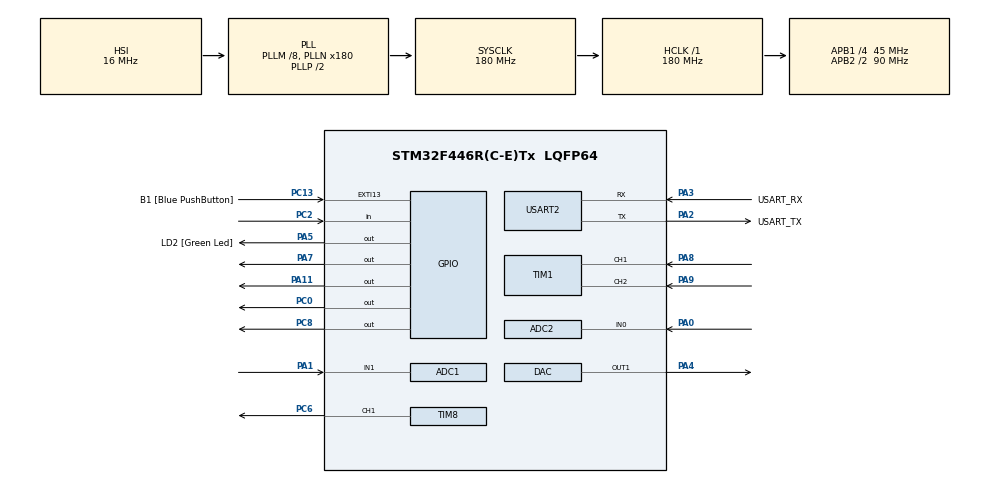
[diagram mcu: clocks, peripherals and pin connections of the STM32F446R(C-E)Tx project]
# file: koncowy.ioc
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ADC1.Channel-0\#ChannelRegularConversion=ADC_CHANNEL_1
ADC1.NbrOfConversionFlag=1
ADC1.Rank-0\#ChannelRegularConversion=1
ADC1.SamplingTime-0\#ChannelRegularConversion=ADC_SAMPLETIME_3CYCLES
ADC1.master=1
ADC2.Channel-0\#ChannelRegularConversion=ADC_CHANNEL_0
ADC2.ClockPrescaler=ADC_CLOCK_SYNC_PCLK_DIV4
ADC2.ContinuousConvMode=DISABLE
ADC2.DMAContinuousRequests=ENABLE
ADC2.ExternalTrigConv=ADC_EXTERNALTRIGCONV_T8_TRGO
ADC2.InjNumberOfConversion=0
ADC2.NbrOfConversionFlag=1
ADC2.Rank-0\#ChannelRegularConversion=1
ADC2.SamplingTime-0\#ChannelRegularConversion=ADC_SAMPLETIME_3CYCLES
Dma.ADC2.0.Direction=DMA_PERIPH_TO_MEMORY
Dma.ADC2.0.FIFOMode=DMA_FIFOMODE_DISABLE
Dma.ADC2.0.Instance=DMA2_Stream2
Dma.ADC2.0.MemDataAlignment=DMA_MDATAALIGN_HALFWORD
Dma.ADC2.0.MemInc=DMA_MINC_ENABLE
Dma.ADC2.0.Mode=DMA_CIRCULAR
Dma.ADC2.0.PeriphDataAlignment=DMA_PDATAALIGN_HALFWORD
Dma.ADC2.0.PeriphInc=DMA_PINC_DISABLE
Dma.ADC2.0.Priority=DMA_PRIORITY_LOW
Dma.Request0=ADC2
Dma.Request1=USART2_RX
Dma.USART2_RX.1.Direction=DMA_PERIPH_TO_MEMORY
Dma.USART2_RX.1.FIFOMode=DMA_FIFOMODE_DISABLE
Dma.USART2_RX.1.Instance=DMA1_Stream5
Dma.USART2_RX.1.MemDataAlignment=DMA_MDATAALIGN_BYTE
Dma.USART2_RX.1.MemInc=DMA_MINC_ENABLE
Dma.USART2_RX.1.Mode=DMA_NORMAL
Dma.USART2_RX.1.PeriphDataAlignment=DMA_PDATAALIGN_BYTE
Dma.USART2_RX.1.PeriphInc=DMA_PINC_DISABLE
Dma.USART2_RX.1.Priority=DMA_PRIORITY_LOW
Mcu.Family=STM32F4
Mcu.Name=STM32F446R(C-E)Tx
Mcu.Package=LQFP64
NVIC.ADC_IRQn=true\:0\:10\:false\:false\:true\:true\:true\:true
NVIC.DMA1_Stream5_IRQn=true\:0\:0\:false\:false\:true\:false\:true\:true
NVIC.DMA2_Stream2_IRQn=true\:0\:2\:false\:false\:true\:false\:true\:true
NVIC.PriorityGroup=NVIC_PRIORITYGROUP_0
NVIC.TIM8_CC_IRQn=true\:0\:6\:false\:false\:true\:true\:true\:true
NVIC.USART2_IRQn=true\:0\:0\:false\:false\:true\:true\:true\:true
PA0-WKUP.Signal=ADCx_IN0
PA1.Signal=ADCx_IN1
PA11.Signal=GPIO_Output
PA13.GPIO_Label=TMS
PA13.Mode=Serial_Wire
PA13.Signal=SYS_JTMS-SWDIO
PA14.GPIO_Label=TCK
PA14.Mode=Serial_Wire
PA14.Signal=SYS_JTCK-SWCLK
PA2.GPIO_Label=USART_TX
PA2.Mode=Asynchronous
PA2.Signal=USART2_TX
PA3.GPIO_Label=USART_RX
PA3.Mode=Asynchronous
PA3.Signal=USART2_RX
PA4.Signal=COMP_DAC1_group
PA5.GPIO_Label=LD2 [Green Led]
PA5.Signal=GPIO_Output
PA7.Signal=GPIO_Output
PA8.Signal=S_TIM1_CH1
PA9.Signal=S_TIM1_CH2
PB3.GPIO_Label=SWO
PB3.Signal=SYS_JTDO-SWO
PC0.Signal=GPIO_Output
PC13.GPIO_Label=B1 [Blue PushButton]
PC13.GPIO_ModeDefaultEXTI=GPIO_MODE_IT_FALLING
PC13.Signal=GPXTI13
PC14-OSC32_IN.Mode=LSE-External-Oscillator
PC14-OSC32_IN.Signal=RCC_OSC32_IN
PC15-OSC32_OUT.Mode=LSE-External-Oscillator
PC15-OSC32_OUT.Signal=RCC_OSC32_OUT
PC2.Signal=GPIO_Input
PC6.Signal=S_TIM8_CH1
PC8.Signal=GPIO_Output
PH0-OSC_IN.Mode=HSE-External-Oscillator
PH0-OSC_IN.Signal=RCC_OSC_IN
PH1-OSC_OUT.Mode=HSE-External-Oscillator
PH1-OSC_OUT.Signal=RCC_OSC_OUT
ProjectManager.HeapSize=0x200
ProjectManager.StackSize=0x400
ProjectManager.TargetToolchain=STM32CubeIDE
RCC.48MHZClocksFreq_Value=84000000
RCC.AHBFreq_Value=180000000
RCC.APB1CLKDivider=RCC_HCLK_DIV4
RCC.APB1Freq_Value=45000000
RCC.APB1TimFreq_Value=90000000
RCC.APB2CLKDivider=RCC_HCLK_DIV2
RCC.APB2Freq_Value=90000000
RCC.APB2TimFreq_Value=180000000
RCC.CortexFreq_Value=180000000
RCC.FLatency-AdvancedSettings=FLASH_LATENCY_5
RCC.HCLKFreq_Value=180000000
RCC.HSE_VALUE=8000000
RCC.HSI_VALUE=16000000
RCC.PLLM=8
RCC.PLLN=180
RCC.SYSCLKFreq_VALUE=180000000
RCC.SYSCLKSource=RCC_SYSCLKSOURCE_PLLCLK
RCC.USBFreq_Value=180000000
RCC.VCOOutputFreq_Value=360000000
SH.ADCx_IN0.0=ADC2_IN0,IN0
SH.ADCx_IN1.0=ADC1_IN1,IN1
SH.COMP_DAC1_group.0=DAC_OUT1,DAC_OUT1
SH.S_TIM1_CH1.0=TIM1_CH1,Encoder_Interface
SH.S_TIM1_CH2.0=TIM1_CH2,Encoder_Interface
SH.S_TIM8_CH1.0=TIM8_CH1,PWM Generation1 CH1
TIM3.Channel-Output\ Compare1\ No\ Output=TIM_CHANNEL_1
TIM6.Prescaler=90
TIM8.Channel-PWM\ Generation1\ CH1=TIM_CHANNEL_1
TIM8.CounterMode=TIM_COUNTERMODE_CENTERALIGNED1
TIM8.Period=5999
TIM8.Pulse-PWM\ Generation1\ CH1=50
TIM8.TIM_MasterOutputTrigger=TIM_TRGO_UPDATE
USART2.VirtualMode=VM_ASYNC
VP_TIM3_VS_no_output1.Mode=Output Compare1 No Output
VP_TIM6_VS_ClockSourceINT.Mode=Enable_Timer
board=NUCLEO-F446RE

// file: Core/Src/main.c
/* USER CODE BEGIN Header */
/**
  ******************************************************************************
  * @file           : main.c
  * @brief          : Main program body
  ******************************************************************************
  * @attention
  *
  * Copyright (c) 2022 STMicroelectronics.
  * All rights reserved.
  *
  * This software is licensed under terms that can be found in the LICENSE file
  * in the root directory of this software component.
  * If no LICENSE file comes with this software, it is provided AS-IS.
  *
  ******************************************************************************
  */
/* USER CODE END Header */
#include "main.h"
#include "adc.h"
#include "dac.h"
#include "dma.h"
#include "tim.h"
#include "usart.h"
#include "gpio.h"

/* USER CODE BEGIN Includes */
#include "pid.h"
/* USER CODE END Includes */

void SystemClock_Config(void);

/* USER CODE BEGIN 0 */

uint16_t current = 0;
float current2 = 0;
/* USER CODE END 0 */

int main(void)
{

  /* MCU Configuration--------------------------------------------------------*/

  /* Reset of all peripherals, Initializes the Flash interface and the Systick. */
  HAL_Init();

  /* Configure the system clock */
  SystemClock_Config();

  /* Initialize all configured peripherals */
  MX_GPIO_Init();
  MX_DMA_Init();
  MX_USART2_UART_Init();
  MX_ADC1_Init();
  MX_ADC2_Init();
  MX_TIM1_Init();
  MX_TIM3_Init();
  MX_TIM8_Init();
  MX_TIM6_Init();
  MX_DAC_Init();
  /* USER CODE BEGIN 2 */
  initPeripherals();
  initMotor();
  /* USER CODE END 2 */

  /* Infinite loop */
  while (1)
  {

    /* USER CODE BEGIN 3 */
	  //testowa();
	  //controlMotor();
	  transmitData();
  }
  /* USER CODE END 3 */
}

void SystemClock_Config(void)
{
  RCC_OscInitTypeDef RCC_OscInitStruct = {0};
  RCC_ClkInitTypeDef RCC_ClkInitStruct = {0};

  /** Configure the main internal regulator output voltage
  */
  __HAL_RCC_PWR_CLK_ENABLE();
  __HAL_PWR_VOLTAGESCALING_CONFIG(PWR_REGULATOR_VOLTAGE_SCALE1);

  /** Initializes the RCC Oscillators according to the specified parameters
  * in the RCC_OscInitTypeDef structure.
  */
  RCC_OscInitStruct.OscillatorType = RCC_OSCILLATORTYPE_HSI;
  RCC_OscInitStruct.HSIState = RCC_HSI_ON;
  RCC_OscInitStruct.HSICalibrationValue = RCC_HSICALIBRATION_DEFAULT;
  RCC_OscInitStruct.PLL.PLLState = RCC_PLL_ON;
  RCC_OscInitStruct.PLL.PLLSource = RCC_PLLSOURCE_HSI;
  RCC_OscInitStruct.PLL.PLLM = 8;
  RCC_OscInitStruct.PLL.PLLN = 180;
  RCC_OscInitStruct.PLL.PLLP = RCC_PLLP_DIV2;
  RCC_OscInitStruct.PLL.PLLQ = 2;
  RCC_OscInitStruct.PLL.PLLR = 2;
  if (HAL_RCC_OscConfig(&RCC_OscInitStruct) != HAL_OK)
  {
    Error_Handler();
  }

  /** Activate the Over-Drive mode
  */
  if (HAL_PWREx_EnableOverDrive() != HAL_OK)
  {
    Error_Handler();
  }

  /** Initializes the CPU, AHB and APB buses clocks
  */
  RCC_ClkInitStruct.ClockType = RCC_CLOCKTYPE_HCLK|RCC_CLOCKTYPE_SYSCLK
                              |RCC_CLOCKTYPE_PCLK1|RCC_CLOCKTYPE_PCLK2;
  RCC_ClkInitStruct.SYSCLKSource = RCC_SYSCLKSOURCE_PLLCLK;
  RCC_ClkInitStruct.AHBCLKDivider = RCC_SYSCLK_DIV1;
  RCC_ClkInitStruct.APB1CLKDivider = RCC_HCLK_DIV4;
  RCC_ClkInitStruct.APB2CLKDivider = RCC_HCLK_DIV2;

  if (HAL_RCC_ClockConfig(&RCC_ClkInitStruct, FLASH_LATENCY_5) != HAL_OK)
  {
    Error_Handler();
  }
}

void Error_Handler(void)
{
  __disable_irq();
  while (1)
  {
  }
}
